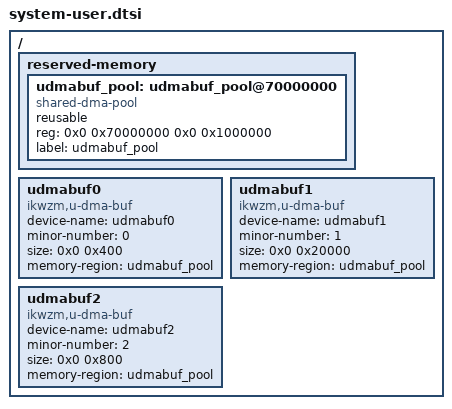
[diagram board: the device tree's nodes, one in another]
/include/ "system-conf.dtsi"
/ {
    reserved-memory {
        #address-cells = <2>;
        #size-cells = <2>;
        ranges;

        udmabuf_pool: udmabuf_pool@70000000 {
            compatible = "shared-dma-pool";
            reusable;
            reg = <0x0 0x70000000 0x0 0x1000000>;
            label = "udmabuf_pool";
        };
    };

    udmabuf0 {
        compatible   = "ikwzm,u-dma-buf";
        device-name  = "udmabuf0";
        minor-number = <0>;
        size         = <0x0 0x400>;
        memory-region = <&udmabuf_pool>;
    };

    udmabuf1 {
        compatible   = "ikwzm,u-dma-buf";
        device-name  = "udmabuf1";
        minor-number = <1>;
        size         = <0x0 0x20000>;
        memory-region = <&udmabuf_pool>;
    };

    udmabuf2 {
        compatible   = "ikwzm,u-dma-buf";
        device-name  = "udmabuf2";
        minor-number = <2>;
        size         = <0x0 0x800>;
        memory-region = <&udmabuf_pool>;
    };
};
